# STM32MP13xx register map
File version: 1.7
CPU: CA7 r0p0, little endian, MPU, FPU, 4 interrupt priority bits
Registers are 32-bit, read-write, reset 0x0 unless marked. A register's access mark holds for its fields unless they carry their own. Offsets are from the block's base; [hi:lo] are bit positions; lines under a group give offsets from that group; 'fields as' and 'values as' point back to an identical list.

## GICV — GICV address block description
Base 0xA0026000
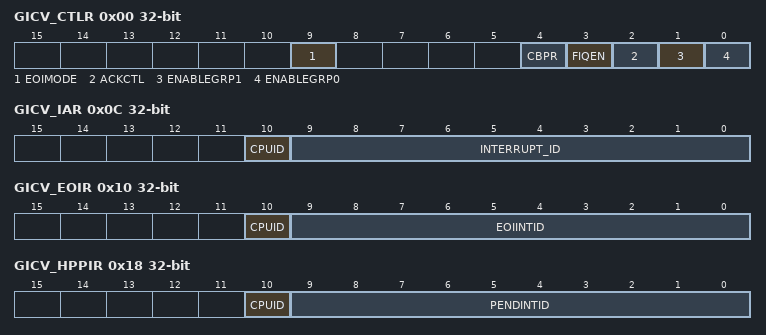
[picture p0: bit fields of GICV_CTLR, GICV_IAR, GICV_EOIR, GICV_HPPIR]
0x00 GICV_CTLR — GICV virtual machine control register
  [9] EOIMODE — end of interrupt mode Controls the behavior associated with the GICV_EOIR, GICV_AEOIR, and GICV_DIR registers.
  [4] CBPR — BPR control Controls whether the GICV_BPR controls both group 0 and group 1 virtual interrupts.
  [3] FIQEN — FIQ enable for group 0 interrupts Controls whether interrupts marked as group 0 are presented as virtual FIQs.
  [2] ACKCTL — acknowledge control Controls whether a read of the GICV_IAR, when the highest priority pending interrupt is a group 1 interrupt, causes the CPU interface to acknowledge the interrupt. Arm deprecates use of this bit. Arm strongly recommends that software is written to operate with this bit always set to 0.
  [1] ENABLEGRP1 — Enables the signaling of group 1 virtual interrupts by the virtual CPU interface to the virtual machine.
  [0] ENABLEGRP0 — Enables the signaling of group 0 virtual interrupts by the virtual CPU interface to the virtual machine.
0x04 GICV_PMR — GICV VM priority mask register
  [7:3] PRIORITY — priority mask level for the virtual CPU interface Only virtual interrupts with higher priority than the value in this register can be signaled to the processor
0x08 GICV_BPR — GICV VM binary point register
  [2:0] BINARY_POINT — The value of this field controls how the 8-bit virtual interrupt priority field is split into a group priority field, used to determine virtual interrupt preemption, and a subpriority field. Minimun value is 2.
0x0C GICV_IAR ro — GICV VM interrupt acknowledge register
  [10] CPUID — If the GICH_LRx.HW bit is set to 0, indicating that the interrupt is triggered in software, then CPUID of the GICH_LRx, that indicate the CPU ID, are returned in the GICV_IAR.CPUID field. Otherwise GICV_IAR.CPUID field reads as zero.
  [9:0] INTERRUPT_ID — The interrupt ID
0x10 GICV_EOIR wo reset not defined
  [10] CPUID — On a multiprocessor implementation, if the write refers to an SGI, this field contains the CPUID value from the corresponding GICV_IAR access.
  [9:0] EOIINTID — If the GICH_LRx.HW bit in the matching list register is set to 1, indicating a hardware interrupt, then a deactivate request is sent to the physical Distributor, identifying the Physical ID from the corresponding field in the list register.
0x14 GICV_RPR ro — GICV VM running priority register
  [7:3] PRIORITY — current running priority on the virtual CPU interface
0x18 GICV_HPPIR ro — GICV VM highest priority pending interrupt register
  [10] CPUID — On a multiprocessor implementation, if GICH_LRx.HW bit=0, this field contains the CPUID value for that virtual interrupt. This identifies the virtual processor that generated the virtual interrupt.
  [9:0] PENDINTID — The virtual interrupt ID of the highest priority pending virtual interrupt
0x1C GICV_ABPR — GICV VM aliased binary point register
  [2:0] BINARY_POINT — The value of this field controls how the 8-bit virtual interrupt priority field is split into a group priority field, used to determine virtual interrupt preemption, and a subpriority field. Minimun value is 3.
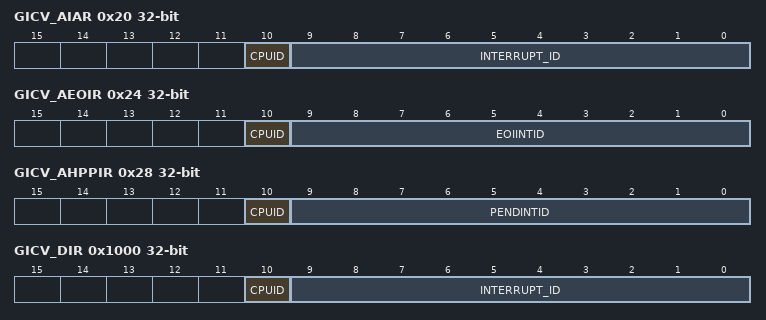
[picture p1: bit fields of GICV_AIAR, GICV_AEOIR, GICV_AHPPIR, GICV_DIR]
0x20 GICV_AIAR ro — GICV VM aliased interrupt register
  [10] CPUID — If the GICH_LRx.HW bit is set to 0, indicating that the interrupt is triggered in software, then CPUID of the GICH_LRx, that indicate the CPU ID, are returned in the GICV_AIAR.CPUID field. Otherwise GICV_AIAR.CPUID field reads as zero..
  [9:0] INTERRUPT_ID — The interrupt ID. If the GICH_LRx.Grp1 bit is 0, the interrupt is Group 0. The spurious interrupt ID 1023 is returned and the interrupt is not acknowledged.
0x24 GICV_AEOIR wo reset not defined
  fields as GICV_EOIR
0x28 GICV_AHPPIR ro — GICV VM aliased highest priority pending interrupt register
  [10] CPUID — If the GICH_LRx.HW bit in the matching List register is set to 1, indicating a hardware interrupt, then a deactivate request is sent to the physical Distributor, identifying the physical ID from the corresponding field in the List register.
  [9:0] PENDINTID — The virtual interrupt ID of the highest-priority pending virtual interrupt, if that virtual interrupt is a group 1 virtual interrupt. Otherwise, the spurious virtual interrupt ID, 1023.
0xD0 GICV_APR0 — GICV VM active priority register
  [31:0] APR0 — active priority
0xFC GICV_IIDR ro reset 0x102143B — GICV VM CPU interface identification register
  [31:0] IIDR — see description of GICC_IIDR register
0x1000 GICV_DIR wo reset not defined
  [10] CPUID — This field identifies the processor that requested the interrupt.
  [9:0] INTERRUPT_ID — The interrupt ID
